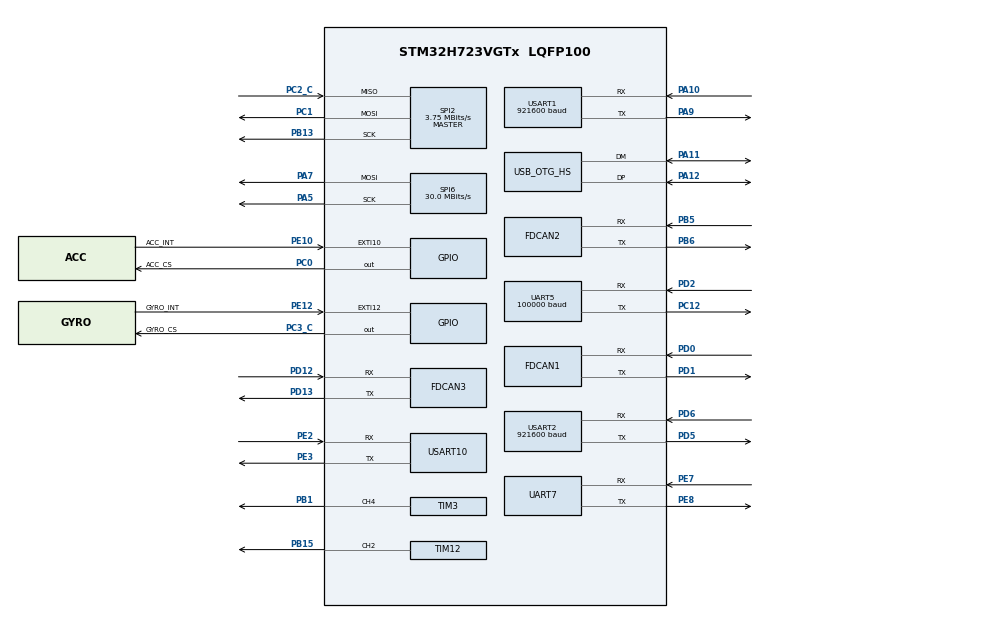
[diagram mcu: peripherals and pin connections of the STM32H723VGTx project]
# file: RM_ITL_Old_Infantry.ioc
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Dma.Request0=SPI2_RX
Dma.Request1=SPI2_TX
Dma.Request10=USART10_TX
Dma.Request2=UART5_RX
Dma.Request3=UART7_RX
Dma.Request4=UART7_TX
Dma.Request5=USART1_RX
Dma.Request6=USART1_TX
Dma.Request7=USART2_RX
Dma.Request8=USART2_TX
Dma.Request9=USART10_RX
Dma.SPI2_RX.0.Direction=DMA_PERIPH_TO_MEMORY
Dma.SPI2_RX.0.EventEnable=DISABLE
Dma.SPI2_RX.0.FIFOMode=DMA_FIFOMODE_DISABLE
Dma.SPI2_RX.0.Instance=DMA1_Stream2
Dma.SPI2_RX.0.MemDataAlignment=DMA_MDATAALIGN_BYTE
Dma.SPI2_RX.0.MemInc=DMA_MINC_ENABLE
Dma.SPI2_RX.0.Mode=DMA_NORMAL
Dma.SPI2_RX.0.PeriphDataAlignment=DMA_PDATAALIGN_BYTE
Dma.SPI2_RX.0.PeriphInc=DMA_PINC_DISABLE
Dma.SPI2_RX.0.Polarity=HAL_DMAMUX_REQ_GEN_RISING
Dma.SPI2_RX.0.Priority=DMA_PRIORITY_VERY_HIGH
Dma.SPI2_RX.0.RequestNumber=1
Dma.SPI2_RX.0.SignalID=NONE
Dma.SPI2_RX.0.SyncEnable=DISABLE
Dma.SPI2_RX.0.SyncPolarity=HAL_DMAMUX_SYNC_NO_EVENT
Dma.SPI2_RX.0.SyncRequestNumber=1
Dma.SPI2_RX.0.SyncSignalID=NONE
Dma.SPI2_TX.1.Direction=DMA_MEMORY_TO_PERIPH
Dma.SPI2_TX.1.EventEnable=DISABLE
Dma.SPI2_TX.1.FIFOMode=DMA_FIFOMODE_DISABLE
Dma.SPI2_TX.1.Instance=DMA1_Stream3
Dma.SPI2_TX.1.MemDataAlignment=DMA_MDATAALIGN_BYTE
Dma.SPI2_TX.1.MemInc=DMA_MINC_ENABLE
Dma.SPI2_TX.1.Mode=DMA_NORMAL
Dma.SPI2_TX.1.PeriphDataAlignment=DMA_PDATAALIGN_BYTE
Dma.SPI2_TX.1.PeriphInc=DMA_PINC_DISABLE
Dma.SPI2_TX.1.Polarity=HAL_DMAMUX_REQ_GEN_RISING
Dma.SPI2_TX.1.Priority=DMA_PRIORITY_HIGH
Dma.SPI2_TX.1.RequestNumber=1
Dma.SPI2_TX.1.SignalID=NONE
Dma.SPI2_TX.1.SyncEnable=DISABLE
Dma.SPI2_TX.1.SyncPolarity=HAL_DMAMUX_SYNC_NO_EVENT
Dma.SPI2_TX.1.SyncRequestNumber=1
Dma.SPI2_TX.1.SyncSignalID=NONE
Dma.UART5_RX.2.Direction=DMA_PERIPH_TO_MEMORY
Dma.UART5_RX.2.EventEnable=DISABLE
Dma.UART5_RX.2.FIFOMode=DMA_FIFOMODE_DISABLE
Dma.UART5_RX.2.Instance=DMA1_Stream5
Dma.UART5_RX.2.MemDataAlignment=DMA_MDATAALIGN_BYTE
Dma.UART5_RX.2.MemInc=DMA_MINC_ENABLE
Dma.UART5_RX.2.Mode=DMA_NORMAL
Dma.UART5_RX.2.PeriphDataAlignment=DMA_PDATAALIGN_BYTE
Dma.UART5_RX.2.PeriphInc=DMA_PINC_DISABLE
Dma.UART5_RX.2.Polarity=HAL_DMAMUX_REQ_GEN_RISING
Dma.UART5_RX.2.Priority=DMA_PRIORITY_LOW
Dma.UART5_RX.2.RequestNumber=1
Dma.UART5_RX.2.SignalID=NONE
Dma.UART5_RX.2.SyncEnable=DISABLE
Dma.UART5_RX.2.SyncPolarity=HAL_DMAMUX_SYNC_NO_EVENT
Dma.UART5_RX.2.SyncRequestNumber=1
Dma.UART5_RX.2.SyncSignalID=NONE
Dma.UART7_RX.3.Direction=DMA_PERIPH_TO_MEMORY
Dma.UART7_RX.3.EventEnable=DISABLE
Dma.UART7_RX.3.FIFOMode=DMA_FIFOMODE_DISABLE
Dma.UART7_RX.3.Instance=DMA1_Stream7
Dma.UART7_RX.3.MemDataAlignment=DMA_MDATAALIGN_BYTE
Dma.UART7_RX.3.MemInc=DMA_MINC_ENABLE
Dma.UART7_RX.3.Mode=DMA_NORMAL
Dma.UART7_RX.3.PeriphDataAlignment=DMA_PDATAALIGN_BYTE
Dma.UART7_RX.3.PeriphInc=DMA_PINC_DISABLE
Dma.UART7_RX.3.Polarity=HAL_DMAMUX_REQ_GEN_RISING
Dma.UART7_RX.3.Priority=DMA_PRIORITY_LOW
Dma.UART7_RX.3.RequestNumber=1
Dma.UART7_RX.3.SignalID=NONE
Dma.UART7_RX.3.SyncEnable=DISABLE
Dma.UART7_RX.3.SyncPolarity=HAL_DMAMUX_SYNC_NO_EVENT
Dma.UART7_RX.3.SyncRequestNumber=1
Dma.UART7_RX.3.SyncSignalID=NONE
Dma.UART7_TX.4.Direction=DMA_MEMORY_TO_PERIPH
Dma.UART7_TX.4.EventEnable=DISABLE
Dma.UART7_TX.4.FIFOMode=DMA_FIFOMODE_DISABLE
Dma.UART7_TX.4.Instance=DMA2_Stream0
Dma.UART7_TX.4.MemDataAlignment=DMA_MDATAALIGN_BYTE
Dma.UART7_TX.4.MemInc=DMA_MINC_ENABLE
Dma.UART7_TX.4.Mode=DMA_NORMAL
Dma.UART7_TX.4.PeriphDataAlignment=DMA_PDATAALIGN_BYTE
Dma.UART7_TX.4.PeriphInc=DMA_PINC_DISABLE
Dma.UART7_TX.4.Polarity=HAL_DMAMUX_REQ_GEN_RISING
Dma.UART7_TX.4.Priority=DMA_PRIORITY_LOW
Dma.UART7_TX.4.RequestNumber=1
Dma.UART7_TX.4.SignalID=NONE
Dma.UART7_TX.4.SyncEnable=DISABLE
Dma.UART7_TX.4.SyncPolarity=HAL_DMAMUX_SYNC_NO_EVENT
Dma.UART7_TX.4.SyncRequestNumber=1
Dma.UART7_TX.4.SyncSignalID=NONE
Dma.USART10_RX.9.Direction=DMA_PERIPH_TO_MEMORY
Dma.USART10_RX.9.EventEnable=DISABLE
Dma.USART10_RX.9.FIFOMode=DMA_FIFOMODE_DISABLE
Dma.USART10_RX.9.Instance=DMA2_Stream1
Dma.USART10_RX.9.MemDataAlignment=DMA_MDATAALIGN_BYTE
Dma.USART10_RX.9.MemInc=DMA_MINC_ENABLE
Dma.USART10_RX.9.Mode=DMA_NORMAL
Dma.USART10_RX.9.PeriphDataAlignment=DMA_PDATAALIGN_BYTE
Dma.USART10_RX.9.PeriphInc=DMA_PINC_DISABLE
Dma.USART10_RX.9.Polarity=HAL_DMAMUX_REQ_GEN_RISING
Dma.USART10_RX.9.Priority=DMA_PRIORITY_LOW
Dma.USART10_RX.9.RequestNumber=1
Dma.USART10_RX.9.SignalID=NONE
Dma.USART10_RX.9.SyncEnable=DISABLE
Dma.USART10_RX.9.SyncPolarity=HAL_DMAMUX_SYNC_NO_EVENT
Dma.USART10_RX.9.SyncRequestNumber=1
Dma.USART10_RX.9.SyncSignalID=NONE
Dma.USART10_TX.10.Direction=DMA_MEMORY_TO_PERIPH
Dma.USART10_TX.10.EventEnable=DISABLE
Dma.USART10_TX.10.FIFOMode=DMA_FIFOMODE_DISABLE
Dma.USART10_TX.10.Instance=DMA2_Stream2
Dma.USART10_TX.10.MemDataAlignment=DMA_MDATAALIGN_BYTE
Dma.USART10_TX.10.MemInc=DMA_MINC_ENABLE
Dma.USART10_TX.10.Mode=DMA_NORMAL
Dma.USART10_TX.10.PeriphDataAlignment=DMA_PDATAALIGN_BYTE
Dma.USART10_TX.10.PeriphInc=DMA_PINC_DISABLE
Dma.USART10_TX.10.Polarity=HAL_DMAMUX_REQ_GEN_RISING
Dma.USART10_TX.10.Priority=DMA_PRIORITY_LOW
Dma.USART10_TX.10.RequestNumber=1
Dma.USART10_TX.10.SignalID=NONE
Dma.USART10_TX.10.SyncEnable=DISABLE
Dma.USART10_TX.10.SyncPolarity=HAL_DMAMUX_SYNC_NO_EVENT
Dma.USART10_TX.10.SyncRequestNumber=1
Dma.USART10_TX.10.SyncSignalID=NONE
Dma.USART1_RX.5.Direction=DMA_PERIPH_TO_MEMORY
Dma.USART1_RX.5.EventEnable=DISABLE
Dma.USART1_RX.5.FIFOMode=DMA_FIFOMODE_DISABLE
Dma.USART1_RX.5.Instance=DMA1_Stream0
Dma.USART1_RX.5.MemDataAlignment=DMA_MDATAALIGN_BYTE
Dma.USART1_RX.5.MemInc=DMA_MINC_ENABLE
Dma.USART1_RX.5.Mode=DMA_NORMAL
Dma.USART1_RX.5.PeriphDataAlignment=DMA_PDATAALIGN_BYTE
Dma.USART1_RX.5.PeriphInc=DMA_PINC_DISABLE
Dma.USART1_RX.5.Polarity=HAL_DMAMUX_REQ_GEN_RISING
Dma.USART1_RX.5.Priority=DMA_PRIORITY_LOW
Dma.USART1_RX.5.RequestNumber=1
Dma.USART1_RX.5.SignalID=NONE
Dma.USART1_RX.5.SyncEnable=DISABLE
Dma.USART1_RX.5.SyncPolarity=HAL_DMAMUX_SYNC_NO_EVENT
Dma.USART1_RX.5.SyncRequestNumber=1
Dma.USART1_RX.5.SyncSignalID=NONE
Dma.USART1_TX.6.Direction=DMA_MEMORY_TO_PERIPH
Dma.USART1_TX.6.EventEnable=DISABLE
Dma.USART1_TX.6.FIFOMode=DMA_FIFOMODE_DISABLE
Dma.USART1_TX.6.Instance=DMA2_Stream6
Dma.USART1_TX.6.MemDataAlignment=DMA_MDATAALIGN_BYTE
Dma.USART1_TX.6.MemInc=DMA_MINC_ENABLE
Dma.USART1_TX.6.Mode=DMA_NORMAL
Dma.USART1_TX.6.PeriphDataAlignment=DMA_PDATAALIGN_BYTE
Dma.USART1_TX.6.PeriphInc=DMA_PINC_DISABLE
Dma.USART1_TX.6.Polarity=HAL_DMAMUX_REQ_GEN_RISING
Dma.USART1_TX.6.Priority=DMA_PRIORITY_LOW
Dma.USART1_TX.6.RequestNumber=1
Dma.USART1_TX.6.SignalID=NONE
Dma.USART1_TX.6.SyncEnable=DISABLE
Dma.USART1_TX.6.SyncPolarity=HAL_DMAMUX_SYNC_NO_EVENT
Dma.USART1_TX.6.SyncRequestNumber=1
Dma.USART1_TX.6.SyncSignalID=NONE
Dma.USART2_RX.7.Direction=DMA_PERIPH_TO_MEMORY
Dma.USART2_RX.7.EventEnable=DISABLE
Dma.USART2_RX.7.FIFOMode=DMA_FIFOMODE_DISABLE
Dma.USART2_RX.7.Instance=DMA1_Stream4
Dma.USART2_RX.7.MemDataAlignment=DMA_MDATAALIGN_BYTE
Dma.USART2_RX.7.MemInc=DMA_MINC_ENABLE
Dma.USART2_RX.7.Mode=DMA_NORMAL
Dma.USART2_RX.7.PeriphDataAlignment=DMA_PDATAALIGN_BYTE
Dma.USART2_RX.7.PeriphInc=DMA_PINC_DISABLE
Dma.USART2_RX.7.Polarity=HAL_DMAMUX_REQ_GEN_RISING
Dma.USART2_RX.7.Priority=DMA_PRIORITY_LOW
Dma.USART2_RX.7.RequestNumber=1
Dma.USART2_RX.7.SignalID=NONE
Dma.USART2_RX.7.SyncEnable=DISABLE
Dma.USART2_RX.7.SyncPolarity=HAL_DMAMUX_SYNC_NO_EVENT
Dma.USART2_RX.7.SyncRequestNumber=1
Dma.USART2_RX.7.SyncSignalID=NONE
Dma.USART2_TX.8.Direction=DMA_MEMORY_TO_PERIPH
Dma.USART2_TX.8.EventEnable=DISABLE
Dma.USART2_TX.8.FIFOMode=DMA_FIFOMODE_DISABLE
Dma.USART2_TX.8.Instance=DMA1_Stream6
Dma.USART2_TX.8.MemDataAlignment=DMA_MDATAALIGN_BYTE
Dma.USART2_TX.8.MemInc=DMA_MINC_ENABLE
Dma.USART2_TX.8.Mode=DMA_NORMAL
Dma.USART2_TX.8.PeriphDataAlignment=DMA_PDATAALIGN_BYTE
Dma.USART2_TX.8.PeriphInc=DMA_PINC_DISABLE
Dma.USART2_TX.8.Polarity=HAL_DMAMUX_REQ_GEN_RISING
Dma.USART2_TX.8.Priority=DMA_PRIORITY_LOW
Dma.USART2_TX.8.RequestNumber=1
Dma.USART2_TX.8.SignalID=NONE
Dma.USART2_TX.8.SyncEnable=DISABLE
Dma.USART2_TX.8.SyncPolarity=HAL_DMAMUX_SYNC_NO_EVENT
Dma.USART2_TX.8.SyncRequestNumber=1
Dma.USART2_TX.8.SyncSignalID=NONE
FDCAN1.CalculateBaudRateNominal=1000000
FDCAN1.CalculateTimeBitNominal=1000
FDCAN1.CalculateTimeQuantumNominal=25.0
FDCAN1.DataPrescaler=3
FDCAN1.DataSyncJumpWidth=10
FDCAN1.DataTimeSeg1=29
FDCAN1.DataTimeSeg2=10
FDCAN1.NominalPrescaler=3
FDCAN1.NominalSyncJumpWidth=10
FDCAN1.NominalTimeSeg1=29
FDCAN1.NominalTimeSeg2=10
FDCAN1.ProtocolException=ENABLE
FDCAN1.RxFifo0ElmtsNbr=32
FDCAN1.RxFifo1ElmtsNbr=32
FDCAN1.StdFiltersNbr=128
FDCAN1.TxFifoQueueElmtsNbr=32
FDCAN2.CalculateBaudRateNominal=1000000
FDCAN2.CalculateTimeBitNominal=1000
FDCAN2.CalculateTimeQuantumNominal=25.0
FDCAN2.DataPrescaler=3
FDCAN2.DataSyncJumpWidth=10
FDCAN2.DataTimeSeg1=29
FDCAN2.DataTimeSeg2=10
FDCAN2.MessageRAMOffset=854
FDCAN2.NominalPrescaler=3
FDCAN2.NominalSyncJumpWidth=10
FDCAN2.NominalTimeSeg1=29
FDCAN2.NominalTimeSeg2=10
FDCAN2.ProtocolException=ENABLE
FDCAN2.RxFifo0ElmtsNbr=32
FDCAN2.RxFifo1ElmtsNbr=32
FDCAN2.StdFiltersNbr=128
FDCAN2.TxFifoQueueElmtsNbr=32
FDCAN3.CalculateBaudRateNominal=1000000
FDCAN3.CalculateTimeBitNominal=1000
FDCAN3.CalculateTimeQuantumNominal=25.0
FDCAN3.DataPrescaler=3
FDCAN3.DataSyncJumpWidth=10
FDCAN3.DataTimeSeg1=29
FDCAN3.DataTimeSeg2=10
FDCAN3.MessageRAMOffset=1706
FDCAN3.NominalPrescaler=3
FDCAN3.NominalSyncJumpWidth=10
FDCAN3.NominalTimeSeg1=29
FDCAN3.NominalTimeSeg2=10
FDCAN3.ProtocolException=ENABLE
FDCAN3.RxFifo0ElmtsNbr=32
FDCAN3.RxFifo1ElmtsNbr=32
FDCAN3.StdFiltersNbr=128
FDCAN3.TxFifoQueueElmtsNbr=32
FREERTOS.INCLUDE_pcTaskGetTaskName=1
FREERTOS.INCLUDE_uxTaskGetStackHighWaterMark2=1
FREERTOS.INCLUDE_vTaskCleanUpResources=1
FREERTOS.INCLUDE_xSemaphoreGetMutexHolder=1
FREERTOS.INCLUDE_xTaskAbortDelay=1
FREERTOS.INCLUDE_xTaskGetHandle=1
FREERTOS.Tasks01=defaultTask,24,512,StartDefaultTask,Default,NULL,Dynamic,NULL,NULL;chassis,24,512,chassis_task,As external,NULL,Static,chassisBuffer,chassisControlBlock;detect,40,512,detect_task,As external,NULL,Static,detectBuffer,detectControlBlock;INS,24,1024,INS_task,As weak,NULL,Static,INSBuffer,INSControlBlock;gimbal,24,512,gimbal_task,As external,NULL,Static,gimbalBuffer,gimbalControlBlock;shoot,24,512,shoot_task,As external,NULL,Static,shootBuffer,shootControlBlock
FREERTOS.configENABLE_FPU=1
FREERTOS.configTOTAL_HEAP_SIZE=30000
Mcu.Family=STM32H7
Mcu.Name=STM32H723VGTx
Mcu.Package=LQFP100
NVIC.DMA1_Stream0_IRQn=true\:5\:0\:false\:false\:true\:true\:false\:true\:true
NVIC.DMA1_Stream2_IRQn=true\:5\:0\:false\:false\:true\:true\:false\:true\:true
NVIC.DMA1_Stream3_IRQn=true\:5\:0\:false\:false\:true\:true\:false\:true\:true
NVIC.DMA1_Stream4_IRQn=true\:5\:0\:false\:false\:true\:true\:false\:true\:true
NVIC.DMA1_Stream5_IRQn=true\:5\:0\:false\:false\:true\:true\:false\:true\:true
NVIC.DMA1_Stream6_IRQn=true\:5\:0\:false\:false\:true\:true\:false\:true\:true
NVIC.DMA1_Stream7_IRQn=true\:5\:0\:false\:false\:true\:true\:false\:true\:true
NVIC.DMA2_Stream0_IRQn=true\:5\:0\:false\:false\:true\:true\:false\:true\:true
NVIC.DMA2_Stream1_IRQn=true\:5\:0\:false\:false\:true\:true\:false\:true\:true
NVIC.DMA2_Stream2_IRQn=true\:5\:0\:false\:false\:true\:true\:false\:true\:true
NVIC.DMA2_Stream6_IRQn=true\:5\:0\:false\:false\:true\:true\:false\:true\:true
NVIC.FDCAN1_IT0_IRQn=true\:5\:0\:false\:false\:true\:true\:true\:true\:true
NVIC.FDCAN1_IT1_IRQn=true\:5\:0\:false\:false\:true\:true\:true\:true\:true
NVIC.FDCAN2_IT0_IRQn=true\:5\:0\:false\:false\:true\:true\:true\:true\:true
NVIC.FDCAN2_IT1_IRQn=true\:5\:0\:false\:false\:true\:true\:true\:true\:true
NVIC.FDCAN3_IT0_IRQn=true\:5\:0\:false\:false\:true\:true\:true\:true\:true
NVIC.FDCAN3_IT1_IRQn=true\:5\:0\:false\:false\:true\:true\:true\:true\:true
NVIC.FDCAN_CAL_IRQn=true\:5\:0\:false\:false\:true\:true\:true\:true\:true
NVIC.OTG_HS_IRQn=true\:5\:0\:false\:false\:true\:true\:true\:true\:true
NVIC.PriorityGroup=NVIC_PRIORITYGROUP_4
NVIC.SPI2_IRQn=true\:5\:0\:false\:false\:true\:true\:false\:true\:true
NVIC.TIM23_IRQn=true\:15\:0\:false\:false\:true\:false\:false\:true\:true
NVIC.TimeBase=TIM23_IRQn
NVIC.TimeBaseIP=TIM23
NVIC.UART5_IRQn=true\:5\:0\:false\:false\:true\:true\:true\:true\:true
NVIC.UART7_IRQn=true\:5\:0\:false\:false\:true\:true\:false\:true\:true
NVIC.USART10_IRQn=true\:5\:0\:false\:false\:true\:true\:false\:true\:true
NVIC.USART1_IRQn=true\:5\:0\:false\:false\:true\:true\:false\:true\:true
NVIC.USART2_IRQn=true\:5\:0\:false\:false\:true\:true\:false\:true\:true
PA10.Mode=Asynchronous
PA10.Signal=USART1_RX
PA11.Mode=Device_Only_FS
PA11.Signal=USB_OTG_HS_DM
PA12.Mode=Device_Only_FS
PA12.Signal=USB_OTG_HS_DP
PA13(JTMS/SWDIO).Mode=Serial_Wire
PA13(JTMS/SWDIO).Signal=DEBUG_JTMS-SWDIO
PA14(JTCK/SWCLK).Mode=Serial_Wire
PA14(JTCK/SWCLK).Signal=DEBUG_JTCK-SWCLK
PA5.Mode=TX_Only_Simplex_Unidirect_Master
PA5.Signal=SPI6_SCK
PA7.Mode=TX_Only_Simplex_Unidirect_Master
PA7.Signal=SPI6_MOSI
PA9.Mode=Asynchronous
PA9.Signal=USART1_TX
PB1.Signal=S_TIM3_CH4
PB13.Mode=Full_Duplex_Master
PB13.Signal=SPI2_SCK
PB15.Signal=S_TIM12_CH2
PB5.Mode=FDCAN_Activate
PB5.Signal=FDCAN2_RX
PB6.Mode=FDCAN_Activate
PB6.Signal=FDCAN2_TX
PC0.GPIO_Label=ACC_CS
PC0.GPIO_Speed=GPIO_SPEED_FREQ_VERY_HIGH
PC0.PinState=GPIO_PIN_SET
PC0.Signal=GPIO_Output
PC1.Mode=Full_Duplex_Master
PC1.Signal=SPI2_MOSI
PC12.Mode=Asynchronous
PC12.Signal=UART5_TX
PC2_C.Mode=Full_Duplex_Master
PC2_C.Signal=SPI2_MISO
PC3_C.GPIO_Label=GYRO_CS
PC3_C.GPIO_Speed=GPIO_SPEED_FREQ_VERY_HIGH
PC3_C.PinState=GPIO_PIN_SET
PC3_C.Signal=GPIO_Output
PD0.Mode=FDCAN_Activate
PD0.Signal=FDCAN1_RX
PD1.Mode=FDCAN_Activate
PD1.Signal=FDCAN1_TX
PD12.Mode=FDCAN_Activate
PD12.Signal=FDCAN3_RX
PD13.Mode=FDCAN_Activate
PD13.Signal=FDCAN3_TX
PD2.Mode=Asynchronous
PD2.Signal=UART5_RX
PD5.Mode=Asynchronous
PD5.Signal=USART2_TX
PD6.Mode=Asynchronous
PD6.Signal=USART2_RX
PE10.GPIO_Label=ACC_INT
PE10.Signal=GPXTI10
PE12.GPIO_Label=GYRO_INT
PE12.Signal=GPXTI12
PE2.Mode=Asynchronous
PE2.Signal=USART10_RX
PE3.Mode=Asynchronous
PE3.Signal=USART10_TX
PE7.Mode=Asynchronous
PE7.Signal=UART7_RX
PE8.Mode=Asynchronous
PE8.Signal=UART7_TX
PH0-OSC_IN.Mode=HSE-External-Oscillator
PH0-OSC_IN.Signal=RCC_OSC_IN
PH1-OSC_OUT.Mode=HSE-External-Oscillator
PH1-OSC_OUT.Signal=RCC_OSC_OUT
ProjectManager.HeapSize=0x200
ProjectManager.StackSize=0x400
ProjectManager.TargetToolchain=MDK-ARM V5.32
RCC.ADCFreq_Value=48375000
RCC.APB1Freq_Value=120000000
RCC.APB2Freq_Value=120000000
RCC.APB3Freq_Value=120000000
RCC.APB4Freq_Value=120000000
RCC.CortexFreq_Value=480000000
RCC.D1PPRE=RCC_APB3_DIV2
RCC.D2PPRE1=RCC_APB1_DIV2
RCC.D2PPRE2=RCC_APB2_DIV2
RCC.D3PPRE=RCC_APB4_DIV2
RCC.DIVM1=2
RCC.DIVN1=40
RCC.DIVP1=1
RCC.DIVQ1=4
RCC.HCLKFreq_Value=240000000
RCC.HPRE=RCC_HCLK_DIV2
RCC.HSE_VALUE=24000000
RCC.PLL2FRACN=0
RCC.PLL3FRACN=0
RCC.PLLFRACN=0
RCC.PLLSourceVirtual=RCC_PLLSOURCE_HSE
RCC.SYSCLKFreq_VALUE=480000000
RCC.SYSCLKSource=RCC_SYSCLKSOURCE_PLLCLK
RCC.USBFreq_Value=120000000
SH.S_TIM12_CH2.0=TIM12_CH2,PWM Generation2 CH2
SH.S_TIM3_CH4.0=TIM3_CH4,PWM Generation4 CH4
SPI2.BaudRatePrescaler=SPI_BAUDRATEPRESCALER_32
SPI2.CLKPhase=SPI_PHASE_2EDGE
SPI2.CLKPolarity=SPI_POLARITY_HIGH
SPI2.CalculateBaudRate=3.75 MBits/s
SPI2.DataSize=SPI_DATASIZE_8BIT
SPI2.Direction=SPI_DIRECTION_2LINES
SPI2.Mode=SPI_MODE_MASTER
SPI2.VirtualType=VM_MASTER
SPI6.BaudRatePrescaler=SPI_BAUDRATEPRESCALER_4
SPI6.CLKPhase=SPI_PHASE_2EDGE
SPI6.CalculateBaudRate=30.0 MBits/s
SPI6.DataSize=SPI_DATASIZE_8BIT
SPI6.Direction=SPI_DIRECTION_2LINES_TXONLY
SPI6.Mode=SPI_MODE_MASTER
SPI6.VirtualType=VM_MASTER
STMicroelectronics.X-CUBE-ALGOBUILD.1.4.0.LibraryCcDSPOoLibraryJjDSPOoLibrary=true
TIM12.Channel-PWM\ Generation2\ CH2=TIM_CHANNEL_2
TIM12.Period=2000-1
TIM12.Prescaler=24-1
TIM12.Pulse-PWM\ Generation2\ CH2=1000
TIM3.AutoReloadPreload=TIM_AUTORELOAD_PRELOAD_ENABLE
TIM3.Channel-PWM\ Generation4\ CH4=TIM_CHANNEL_4
TIM3.Period=10000-1
TIM3.Prescaler=24-1
UART5.BaudRate=100000
UART5.Mode=MODE_RX
UART5.Parity=PARITY_EVEN
UART5.StopBits=UART_STOPBITS_2
UART5.WordLength=WORDLENGTH_9B
USART1.BaudRate=921600
USART1.VirtualMode-Asynchronous=VM_ASYNC
USART10.VirtualMode=VM_ASYNC
USART2.BaudRate=921600
USART2.VirtualMode-Asynchronous=VM_ASYNC
USB_DEVICE.CLASS_NAME_HS=CDC
USB_DEVICE.VirtualMode=Cdc
USB_DEVICE.VirtualModeHS=Cdc_HS
USB_OTG_HS.VirtualMode-Device_Only_FS=Device_Only_FS
VP_FREERTOS_VS_CMSIS_V2.Mode=CMSIS_V2
VP_MEMORYMAP_VS_MEMORYMAP.Mode=CurAppReg
VP_STMicroelectronics.X-CUBE-ALGOBUILD_VS_DSPOoLibraryJjLibrary_1.4.0_1.4.0.Mode=DSPOoLibraryJjLibrary
VP_SYS_VS_tim23.Mode=TIM23
VP_USB_DEVICE_VS_USB_DEVICE_CDC_HS.Mode=CDC_HS
board=custom

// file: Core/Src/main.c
/* USER CODE BEGIN Header */
/**
  ******************************************************************************
  * @file           : main.c
  * @brief          : Main program body
  ******************************************************************************
  * @attention
  *
  * Copyright (c) 2026 STMicroelectronics.
  * All rights reserved.
  *
  * This software is licensed under terms that can be found in the LICENSE file
  * in the root directory of this software component.
  * If no LICENSE file comes with this software, it is provided AS-IS.
  *
  ******************************************************************************
  */
/* USER CODE END Header */
#include "main.h"
#include "cmsis_os.h"
#include "dma.h"
#include "fdcan.h"
#include "spi.h"
#include "tim.h"
#include "usart.h"
#include "usb_device.h"
#include "gpio.h"

/* USER CODE BEGIN Includes */
#include "bsp_can.h"
#include "bsp_usart.h"
#include "remote_control.h"
/* USER CODE END Includes */

void SystemClock_Config(void);
void MX_FREERTOS_Init(void);

int main(void)
{

  /* MCU Configuration--------------------------------------------------------*/

  /* Reset of all peripherals, Initializes the Flash interface and the Systick. */
  HAL_Init();

  /* Configure the system clock */
  SystemClock_Config();

  /* Initialize all configured peripherals */
  MX_GPIO_Init();
  MX_DMA_Init();
  MX_FDCAN1_Init();
  MX_FDCAN2_Init();
  MX_FDCAN3_Init();
  MX_SPI2_Init();
  MX_SPI6_Init();
  MX_UART5_Init();
  MX_UART7_Init();
  MX_USART1_UART_Init();
  MX_USART2_UART_Init();
  MX_USART10_UART_Init();
  MX_TIM3_Init();
  MX_TIM12_Init();
  /* USER CODE BEGIN 2 */
	bsp_can_init();
		usart_rx_dma_start(&huart1, usart1_rx_buf, sizeof(usart1_rx_buf));  // USART1 DMA���ճ�ʼ��
    usart_rx_dma_start(&huart5, sbus_buf, sizeof(sbus_buf));            // SBUSң����DMA���ճ�ʼ��
    usart_rx_dma_start(&huart7, usart7_rx_buf, sizeof(usart7_rx_buf));  // USART7 DMA���ճ�ʼ��
    usart_rx_dma_start(&huart10, uart10_rx_data_t[uart10_buff_ctrl].buffer, UART_BUFFER_SIZE);  // USART10 DMA���ճ�ʼ��
		remote_control_init();
  /* USER CODE END 2 */

  /* Init scheduler */
  osKernelInitialize();  /* Call init function for freertos objects (in cmsis_os2.c) */
  MX_FREERTOS_Init();

  /* Start scheduler */
  osKernelStart();

  /* We should never get here as control is now taken by the scheduler */

  /* Infinite loop */
  while (1)
  {

  }
}

void SystemClock_Config(void)
{
  RCC_OscInitTypeDef RCC_OscInitStruct = {0};
  RCC_ClkInitTypeDef RCC_ClkInitStruct = {0};

  /** Supply configuration update enable
  */
  HAL_PWREx_ConfigSupply(PWR_LDO_SUPPLY);

  /** Configure the main internal regulator output voltage
  */
  __HAL_PWR_VOLTAGESCALING_CONFIG(PWR_REGULATOR_VOLTAGE_SCALE0);

  while(!__HAL_PWR_GET_FLAG(PWR_FLAG_VOSRDY)) {}

  /** Initializes the RCC Oscillators according to the specified parameters
  * in the RCC_OscInitTypeDef structure.
  */
  RCC_OscInitStruct.OscillatorType = RCC_OSCILLATORTYPE_HSE;
  RCC_OscInitStruct.HSEState = RCC_HSE_ON;
  RCC_OscInitStruct.PLL.PLLState = RCC_PLL_ON;
  RCC_OscInitStruct.PLL.PLLSource = RCC_PLLSOURCE_HSE;
  RCC_OscInitStruct.PLL.PLLM = 2;
  RCC_OscInitStruct.PLL.PLLN = 40;
  RCC_OscInitStruct.PLL.PLLP = 1;
  RCC_OscInitStruct.PLL.PLLQ = 4;
  RCC_OscInitStruct.PLL.PLLR = 2;
  RCC_OscInitStruct.PLL.PLLRGE = RCC_PLL1VCIRANGE_3;
  RCC_OscInitStruct.PLL.PLLVCOSEL = RCC_PLL1VCOWIDE;
  RCC_OscInitStruct.PLL.PLLFRACN = 0;
  if (HAL_RCC_OscConfig(&RCC_OscInitStruct) != HAL_OK)
  {
    Error_Handler();
  }

  /** Initializes the CPU, AHB and APB buses clocks
  */
  RCC_ClkInitStruct.ClockType = RCC_CLOCKTYPE_HCLK|RCC_CLOCKTYPE_SYSCLK
                              |RCC_CLOCKTYPE_PCLK1|RCC_CLOCKTYPE_PCLK2
                              |RCC_CLOCKTYPE_D3PCLK1|RCC_CLOCKTYPE_D1PCLK1;
  RCC_ClkInitStruct.SYSCLKSource = RCC_SYSCLKSOURCE_PLLCLK;
  RCC_ClkInitStruct.SYSCLKDivider = RCC_SYSCLK_DIV1;
  RCC_ClkInitStruct.AHBCLKDivider = RCC_HCLK_DIV2;
  RCC_ClkInitStruct.APB3CLKDivider = RCC_APB3_DIV2;
  RCC_ClkInitStruct.APB1CLKDivider = RCC_APB1_DIV2;
  RCC_ClkInitStruct.APB2CLKDivider = RCC_APB2_DIV2;
  RCC_ClkInitStruct.APB4CLKDivider = RCC_APB4_DIV2;

  if (HAL_RCC_ClockConfig(&RCC_ClkInitStruct, FLASH_LATENCY_3) != HAL_OK)
  {
    Error_Handler();
  }
}

void HAL_TIM_PeriodElapsedCallback(TIM_HandleTypeDef *htim)
{
  if (htim->Instance == TIM23)
  {
    HAL_IncTick();
  }
}

void Error_Handler(void)
{
  __disable_irq();
  while (1)
  {
  }
}

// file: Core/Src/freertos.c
/* USER CODE BEGIN Header */
/**
  ******************************************************************************
  * File Name          : freertos.c
  * Description        : Code for freertos applications
  ******************************************************************************
  * @attention
  *
  * Copyright (c) 2026 STMicroelectronics.
  * All rights reserved.
  *
  * This software is licensed under terms that can be found in the LICENSE file
  * in the root directory of this software component.
  * If no LICENSE file comes with this software, it is provided AS-IS.
  *
  ******************************************************************************
  */
/* USER CODE END Header */

#include "FreeRTOS.h"
#include "task.h"
#include "main.h"
#include "cmsis_os.h"

typedef StaticTask_t osStaticThreadDef_t;

/* Definitions for defaultTask */
osThreadId_t defaultTaskHandle;
const osThreadAttr_t defaultTask_attributes = {
  .name = "defaultTask",
  .stack_size = 512 * 4,
  .priority = (osPriority_t) osPriorityNormal,
};
/* Definitions for chassis */
osThreadId_t chassisHandle;
uint32_t chassisBuffer[ 512 ];
osStaticThreadDef_t chassisControlBlock;
const osThreadAttr_t chassis_attributes = {
  .name = "chassis",
  .cb_mem = &chassisControlBlock,
  .cb_size = sizeof(chassisControlBlock),
  .stack_mem = &chassisBuffer[0],
  .stack_size = sizeof(chassisBuffer),
  .priority = (osPriority_t) osPriorityNormal,
};
/* Definitions for detect */
osThreadId_t detectHandle;
uint32_t detectBuffer[ 512 ];
osStaticThreadDef_t detectControlBlock;
const osThreadAttr_t detect_attributes = {
  .name = "detect",
  .cb_mem = &detectControlBlock,
  .cb_size = sizeof(detectControlBlock),
  .stack_mem = &detectBuffer[0],
  .stack_size = sizeof(detectBuffer),
  .priority = (osPriority_t) osPriorityHigh,
};
/* Definitions for INS */
osThreadId_t INSHandle;
uint32_t INSBuffer[ 1024 ];
osStaticThreadDef_t INSControlBlock;
const osThreadAttr_t INS_attributes = {
  .name = "INS",
  .cb_mem = &INSControlBlock,
  .cb_size = sizeof(INSControlBlock),
  .stack_mem = &INSBuffer[0],
  .stack_size = sizeof(INSBuffer),
  .priority = (osPriority_t) osPriorityNormal,
};
/* Definitions for gimbal */
osThreadId_t gimbalHandle;
uint32_t gimbalBuffer[ 512 ];
osStaticThreadDef_t gimbalControlBlock;
const osThreadAttr_t gimbal_attributes = {
  .name = "gimbal",
  .cb_mem = &gimbalControlBlock,
  .cb_size = sizeof(gimbalControlBlock),
  .stack_mem = &gimbalBuffer[0],
  .stack_size = sizeof(gimbalBuffer),
  .priority = (osPriority_t) osPriorityNormal,
};
/* Definitions for shoot */
osThreadId_t shootHandle;
uint32_t shootBuffer[ 512 ];
osStaticThreadDef_t shootControlBlock;
const osThreadAttr_t shoot_attributes = {
  .name = "shoot",
  .cb_mem = &shootControlBlock,
  .cb_size = sizeof(shootControlBlock),
  .stack_mem = &shootBuffer[0],
  .stack_size = sizeof(shootBuffer),
  .priority = (osPriority_t) osPriorityNormal,
};

void StartDefaultTask(void *argument);
extern void chassis_task(void *argument);
extern void detect_task(void *argument);
void INS_task(void *argument);
extern void gimbal_task(void *argument);
extern void shoot_task(void *argument);

extern void MX_USB_DEVICE_Init(void);
void MX_FREERTOS_Init(void); /* (MISRA C 2004 rule 8.1) */

void MX_FREERTOS_Init(void) {

  /* Create the thread(s) */
  /* creation of defaultTask */
  defaultTaskHandle = osThreadNew(StartDefaultTask, NULL, &defaultTask_attributes);

  /* creation of chassis */
  chassisHandle = osThreadNew(chassis_task, NULL, &chassis_attributes);

  /* creation of detect */
  detectHandle = osThreadNew(detect_task, NULL, &detect_attributes);

  /* creation of INS */
  INSHandle = osThreadNew(INS_task, NULL, &INS_attributes);

  /* creation of gimbal */
  gimbalHandle = osThreadNew(gimbal_task, NULL, &gimbal_attributes);

  /* creation of shoot */
  shootHandle = osThreadNew(shoot_task, NULL, &shoot_attributes);

}

void StartDefaultTask(void *argument)
{
  /* init code for USB_DEVICE */
  MX_USB_DEVICE_Init();
  for(;;)
  {
    osDelay(1);
  }
}

__weak void INS_task(void *argument)
{
  for(;;)
  {
    osDelay(1);
  }
}
